AUTOSAR XML (schema 4-0-3)
package /ComponentTypes
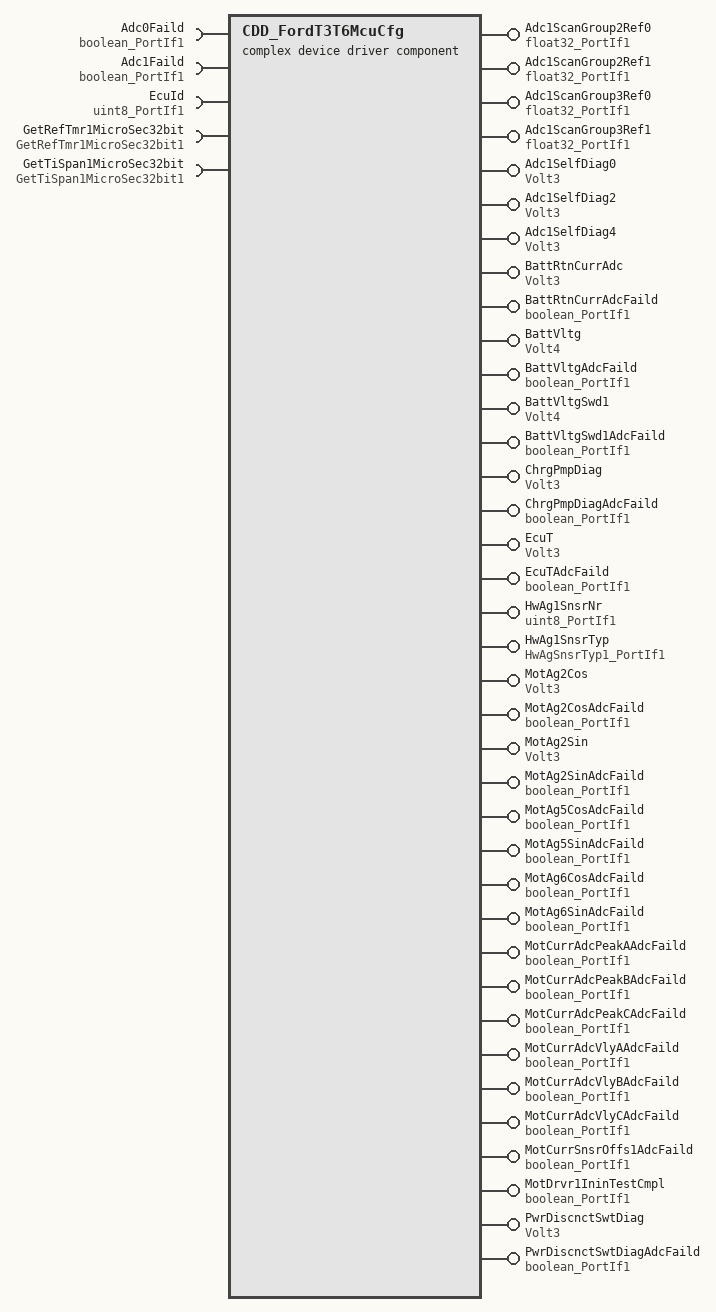
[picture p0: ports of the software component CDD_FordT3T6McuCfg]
  complex device driver sw component type CDD_FordT3T6McuCfg
    37 x provide port:
      Adc1ScanGroup2Ref0: nonqueued-sender-com-spec{data-element=Val, init-value=0}, provided-interface=float32_PortIf1
      Adc1ScanGroup2Ref1: nonqueued-sender-com-spec{data-element=Val, init-value=0}, provided-interface=float32_PortIf1
      Adc1ScanGroup3Ref0: nonqueued-sender-com-spec{data-element=Val, init-value=0}, provided-interface=float32_PortIf1
      Adc1ScanGroup3Ref1: nonqueued-sender-com-spec{data-element=Val, init-value=0}, provided-interface=float32_PortIf1
      Adc1SelfDiag0: nonqueued-sender-com-spec{data-element=Val, init-value=0}, provided-interface=Volt3
      Adc1SelfDiag2: nonqueued-sender-com-spec{data-element=Val, init-value=0}, provided-interface=Volt3
      Adc1SelfDiag4: nonqueued-sender-com-spec{data-element=Val, init-value=0}, provided-interface=Volt3
      BattRtnCurrAdc: nonqueued-sender-com-spec{data-element=Val, init-value=0}, provided-interface=Volt3
      BattRtnCurrAdcFaild: nonqueued-sender-com-spec{data-element=Logl, init-value=0}, provided-interface=boolean_PortIf1
      BattVltg: nonqueued-sender-com-spec{data-element=Val, init-value=0}, provided-interface=Volt4
      BattVltgAdcFaild: nonqueued-sender-com-spec{data-element=Logl, init-value=0}, provided-interface=boolean_PortIf1
      BattVltgSwd1: nonqueued-sender-com-spec{data-element=Val, init-value=0}, provided-interface=Volt4
      BattVltgSwd1AdcFaild: nonqueued-sender-com-spec{data-element=Logl, init-value=0}, provided-interface=boolean_PortIf1
      ChrgPmpDiag: nonqueued-sender-com-spec{data-element=Val, init-value=0}, provided-interface=Volt3
      ChrgPmpDiagAdcFaild: nonqueued-sender-com-spec{data-element=Logl, init-value=0}, provided-interface=boolean_PortIf1
      EcuT: nonqueued-sender-com-spec{data-element=Val, init-value=0}, provided-interface=Volt3
      EcuTAdcFaild: nonqueued-sender-com-spec{data-element=Logl, init-value=0}, provided-interface=boolean_PortIf1
      HwAg1SnsrNr: nonqueued-sender-com-spec{data-element=Val, init-value=0}, provided-interface=uint8_PortIf1
      HwAg1SnsrTyp: nonqueued-sender-com-spec{data-element=Val, init-value=0}, provided-interface=HwAgSnsrTyp1_PortIf1
      MotAg2Cos: nonqueued-sender-com-spec{data-element=Val, init-value=0}, provided-interface=Volt3
      MotAg2CosAdcFaild: nonqueued-sender-com-spec{data-element=Logl, init-value=0}, provided-interface=boolean_PortIf1
      MotAg2Sin: nonqueued-sender-com-spec{data-element=Val, init-value=0}, provided-interface=Volt3
      MotAg2SinAdcFaild: nonqueued-sender-com-spec{data-element=Logl, init-value=0}, provided-interface=boolean_PortIf1
      MotAg5CosAdcFaild: nonqueued-sender-com-spec{data-element=Logl, init-value=0}, provided-interface=boolean_PortIf1
      MotAg5SinAdcFaild: nonqueued-sender-com-spec{data-element=Logl, init-value=0}, provided-interface=boolean_PortIf1
      MotAg6CosAdcFaild: nonqueued-sender-com-spec{data-element=Logl, init-value=0}, provided-interface=boolean_PortIf1
      MotAg6SinAdcFaild: nonqueued-sender-com-spec{data-element=Logl, init-value=0}, provided-interface=boolean_PortIf1
      MotCurrAdcPeakAAdcFaild: nonqueued-sender-com-spec{data-element=Logl, init-value=0}, provided-interface=boolean_PortIf1
      MotCurrAdcPeakBAdcFaild: nonqueued-sender-com-spec{data-element=Logl, init-value=0}, provided-interface=boolean_PortIf1
      MotCurrAdcPeakCAdcFaild: nonqueued-sender-com-spec{data-element=Logl, init-value=0}, provided-interface=boolean_PortIf1
      MotCurrAdcVlyAAdcFaild: nonqueued-sender-com-spec{data-element=Logl, init-value=0}, provided-interface=boolean_PortIf1
      MotCurrAdcVlyBAdcFaild: nonqueued-sender-com-spec{data-element=Logl, init-value=0}, provided-interface=boolean_PortIf1
      MotCurrAdcVlyCAdcFaild: nonqueued-sender-com-spec{data-element=Logl, init-value=0}, provided-interface=boolean_PortIf1
      MotCurrSnsrOffs1AdcFaild: nonqueued-sender-com-spec{data-element=Logl, init-value=0}, provided-interface=boolean_PortIf1
      MotDrvr1IninTestCmpl: nonqueued-sender-com-spec{data-element=Logl, init-value=0}, provided-interface=boolean_PortIf1
      PwrDiscnctSwtDiag: nonqueued-sender-com-spec{data-element=Val, init-value=0}, provided-interface=Volt3
      PwrDiscnctSwtDiagAdcFaild: nonqueued-sender-com-spec{data-element=Logl, init-value=0}, provided-interface=boolean_PortIf1
    5 x require port:
      Adc0Faild: nonqueued-receiver-com-spec{data-element=Logl, filter=data-filter-type=ALWAYS, init-value=0}, required-interface=boolean_PortIf1
      Adc1Faild: nonqueued-receiver-com-spec{data-element=Logl, filter=data-filter-type=ALWAYS, init-value=0}, required-interface=boolean_PortIf1
      EcuId: nonqueued-receiver-com-spec{data-element=Val, filter=data-filter-type=ALWAYS, init-value=0}, required-interface=uint8_PortIf1
      GetRefTmr1MicroSec32bit: client-com-spec=Oper, required-interface=GetRefTmr1MicroSec32bit1
      GetTiSpan1MicroSec32bit: client-com-spec=Oper, required-interface=GetTiSpan1MicroSec32bit1
    behavior CDD_FordT3T6McuCfg_InternalBehavior: data-type-mapping=Nexteer
      6 x timing event:
        FordT3T6McuCfgInit{2..5}_InitEvent: start-on-event=FordT3T6McuCfgInit{2..5}, period=0
        TMT_FordT3T6McuCfgPer2: start-on-event=FordT3T6McuCfgPer2, period=0.002
        TMT_FordT3T6McuCfgPer3: start-on-event=FordT3T6McuCfgPer3, period=0.002
      6 x runnable:
        FordT3T6McuCfgInit2
        FordT3T6McuCfgInit3
          sync call SC_GetRefTmr1MicroSec32bit_Oper: operation=GetRefTmr1MicroSec32bit.Oper, timeout=0
          sync call SC_GetTiSpan1MicroSec32bit_Oper: operation=GetTiSpan1MicroSec32bit.Oper, timeout=0
        FordT3T6McuCfgInit4
          data-send-points:
            15 x access:
              SEND_Adc1ScanGroup2Ref0_Val: accessed-variable=Adc1ScanGroup2Ref0.Val
              SEND_Adc1ScanGroup2Ref1_Val: accessed-variable=Adc1ScanGroup2Ref1.Val
              SEND_Adc1ScanGroup3Ref0_Val: accessed-variable=Adc1ScanGroup3Ref0.Val
              SEND_Adc1ScanGroup3Ref1_Val: accessed-variable=Adc1ScanGroup3Ref1.Val
              SEND_Adc1SelfDiag0_Val: accessed-variable=Adc1SelfDiag0.Val
              SEND_Adc1SelfDiag2_Val: accessed-variable=Adc1SelfDiag2.Val
              SEND_Adc1SelfDiag4_Val: accessed-variable=Adc1SelfDiag4.Val
              SEND_BattRtnCurrAdc_Val: accessed-variable=BattRtnCurrAdc.Val
              SEND_BattVltg_Val: accessed-variable=BattVltg.Val
              SEND_BattVltgSwd1_Val: accessed-variable=BattVltgSwd1.Val
              SEND_ChrgPmpDiag_Val: accessed-variable=ChrgPmpDiag.Val
              SEND_EcuT_Val: accessed-variable=EcuT.Val
              SEND_MotAg2Cos_Val: accessed-variable=MotAg2Cos.Val
              SEND_MotAg2Sin_Val: accessed-variable=MotAg2Sin.Val
              SEND_PwrDiscnctSwtDiag_Val: accessed-variable=PwrDiscnctSwtDiag.Val
        FordT3T6McuCfgInit5
          data-receive-point-by-arguments:
            access SEND_EcuId_Val: accessed-variable=EcuId.Val
          data-send-points:
            access SEND_HwAg1SnsrNr_Val: accessed-variable=HwAg1SnsrNr.Val
            access SEND_HwAg1SnsrTyp_Val: accessed-variable=HwAg1SnsrTyp.Val
        FordT3T6McuCfgPer2
          data-send-points:
            15 x access:
              SEND_Adc1ScanGroup2Ref0_Val: accessed-variable=Adc1ScanGroup2Ref0.Val
              SEND_Adc1ScanGroup2Ref1_Val: accessed-variable=Adc1ScanGroup2Ref1.Val
              SEND_Adc1ScanGroup3Ref0_Val: accessed-variable=Adc1ScanGroup3Ref0.Val
              SEND_Adc1ScanGroup3Ref1_Val: accessed-variable=Adc1ScanGroup3Ref1.Val
              SEND_Adc1SelfDiag0_Val: accessed-variable=Adc1SelfDiag0.Val
              SEND_Adc1SelfDiag2_Val: accessed-variable=Adc1SelfDiag2.Val
              SEND_Adc1SelfDiag4_Val: accessed-variable=Adc1SelfDiag4.Val
              SEND_BattRtnCurrAdc_Val: accessed-variable=BattRtnCurrAdc.Val
              SEND_BattVltg_Val: accessed-variable=BattVltg.Val
              SEND_BattVltgSwd1_Val: accessed-variable=BattVltgSwd1.Val
              SEND_ChrgPmpDiag_Val: accessed-variable=ChrgPmpDiag.Val
              SEND_EcuT_Val: accessed-variable=EcuT.Val
              SEND_MotAg2Cos_Val: accessed-variable=MotAg2Cos.Val
              SEND_MotAg2Sin_Val: accessed-variable=MotAg2Sin.Val
              SEND_PwrDiscnctSwtDiag_Val: accessed-variable=PwrDiscnctSwtDiag.Val
        FordT3T6McuCfgPer3
          data-receive-point-by-arguments:
            access REC_Adc0Faild_Logl: accessed-variable=Adc0Faild.Logl
            access REC_Adc1Faild_Logl: accessed-variable=Adc1Faild.Logl
          data-send-points:
            22 x access:
              SEND_BattRtnCurrAdcFaild_Logl: accessed-variable=BattRtnCurrAdcFaild.Logl
              SEND_BattVltgAdcFaild_Logl: accessed-variable=BattVltgAdcFaild.Logl
              SEND_BattVltgSwd1AdcFaild_Logl: accessed-variable=BattVltgSwd1AdcFaild.Logl
              SEND_ChrgPmpDiagAdcFaild_Logl: accessed-variable=ChrgPmpDiagAdcFaild.Logl
              SEND_EcuTAdcFaild_Logl: accessed-variable=EcuTAdcFaild.Logl
              SEND_HwAg1SnsrNr_Val: accessed-variable=HwAg1SnsrNr.Val
              SEND_HwAg1SnsrTyp_Val: accessed-variable=HwAg1SnsrTyp.Val
              SEND_MotAg2CosAdcFaild_Logl: accessed-variable=MotAg5CosAdcFaild.Logl
              SEND_MotAg2CosAdcFaild_Logl_1: accessed-variable=MotAg2CosAdcFaild.Logl
              SEND_MotAg2SinAdcFaild_Logl: accessed-variable=MotAg5SinAdcFaild.Logl
              SEND_MotAg2SinAdcFaild_Logl_1: accessed-variable=MotAg2SinAdcFaild.Logl
              SEND_MotAg6CosAdcFaild_Logl: accessed-variable=MotAg6CosAdcFaild.Logl
              SEND_MotAg6SinAdcFaild_Logl: accessed-variable=MotAg6SinAdcFaild.Logl
              SEND_MotCurrAdcPeakAAdcFaild_Logl: accessed-variable=MotCurrAdcPeakAAdcFaild.Logl
              SEND_MotCurrAdcPeakBAdcFaild_Logl: accessed-variable=MotCurrAdcPeakBAdcFaild.Logl
              SEND_MotCurrAdcPeakCAdcFaild_Logl: accessed-variable=MotCurrAdcPeakCAdcFaild.Logl
              SEND_MotCurrAdcVlyAAdcFaild_Logl: accessed-variable=MotCurrAdcVlyAAdcFaild.Logl
              SEND_MotCurrAdcVlyBAdcFaild_Logl: accessed-variable=MotCurrAdcVlyBAdcFaild.Logl
              SEND_MotCurrAdcVlyCAdcFaild_Logl: accessed-variable=MotCurrAdcVlyCAdcFaild.Logl
              SEND_MotCurrSnsrOffs1AdcFaild_Logl: accessed-variable=MotCurrSnsrOffs1AdcFaild.Logl
              SEND_MotDrvr1IninTestCmpl_Logl: accessed-variable=MotDrvr1IninTestCmpl.Logl
              SEND_PwrDiscnctSwtDiagAdcFaild_Logl: accessed-variable=PwrDiscnctSwtDiagAdcFaild.Logl
  swc implementation CDD_FordT3T6McuCfg_Implementation: behavior=CDD_FordT3T6McuCfg_InternalBehavior
    code-descriptors:
      code Default: artifact-descriptors=autosar-engineering-object={short-label=Default, category=SWSRC}
